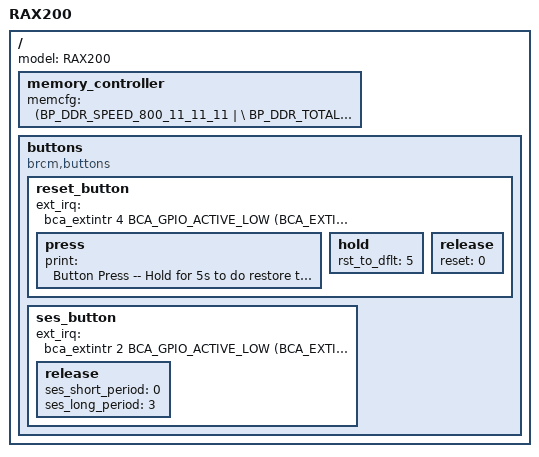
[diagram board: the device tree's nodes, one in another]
#include "4908.dtsi"

/ {
    model="RAX200";
    memory_controller {
        memcfg = <(BP_DDR_SPEED_800_11_11_11 | \
                   BP_DDR_TOTAL_SIZE_1024MB  | \
                   BP_DDR_DEVICE_WIDTH_16    | \
                   BP_DDR_TOTAL_WIDTH_32BIT  | \
                   BP_DDR_SSC_CONFIG_1)>;
    };

	buttons {
		compatible = "brcm,buttons";
		reset_button {
			ext_irq = <&bca_extintr 4 BCA_GPIO_ACTIVE_LOW (BCA_EXTINTR_TYPE_LOW_LEVEL | BCA_EXTINTR_TYPE_SENSE_LEVEL)>;
			press {
				print = "Button Press -- Hold for 5s to do restore to default";
			};
			hold {
				rst_to_dflt = <5>;
			};
			release {
				reset = <0>;
			};	
		};
		ses_button {
			ext_irq = <&bca_extintr 2 BCA_GPIO_ACTIVE_LOW (BCA_EXTINTR_TYPE_LOW_LEVEL | BCA_EXTINTR_TYPE_SENSE_LEVEL)>;
			release {
				ses_short_period = <0>;
				ses_long_period = <3>;
			};
		};
	};
};

